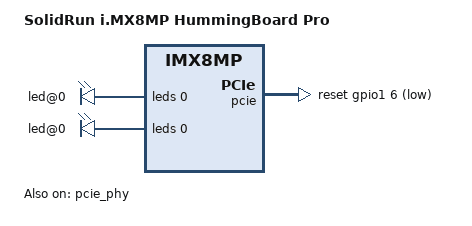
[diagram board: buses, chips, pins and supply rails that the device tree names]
// SPDX-License-Identifier: (GPL-2.0+ OR MIT)
/*
 * Copyright 2025 Josua Mayer <josua@solid-run.com>
 */

/dts-v1/;

#include <dt-bindings/phy/phy-imx8-pcie.h>

#include "imx8mp-sr-som.dtsi"
#include "imx8mp-hummingboard-pulse-codec.dtsi"
#include "imx8mp-hummingboard-pulse-common.dtsi"
#include "imx8mp-hummingboard-pulse-hdmi.dtsi"
#include "imx8mp-hummingboard-pulse-m2con.dtsi"
#include "imx8mp-hummingboard-pulse-mini-hdmi.dtsi"

/ {
	model = "SolidRun i.MX8MP HummingBoard Pro";
	compatible = "solidrun,imx8mp-hummingboard-pro",
		     "solidrun,imx8mp-sr-som", "fsl,imx8mp";

	aliases {
		ethernet0 = &eqos;
		ethernet1 = &fec;
	};
};

&iomuxc {
	pinctrl-names = "default";
	pinctrl-0 = <&mikro_pwm_pins>, <&mikro_int_pins>, <&hdmi_pins>,
		    <&m2_wwan_wake_pins>;
};

&pcie {
	pinctrl-0 = <&m2_reset_pins>;
	pinctrl-names = "default";
	reset-gpio = <&gpio1 6 GPIO_ACTIVE_LOW>;
	status = "okay";
};

&pcie_phy {
	clocks = <&hsio_blk_ctrl>;
	clock-names = "ref";
	fsl,clkreq-unsupported;
	fsl,refclk-pad-mode = <IMX8_PCIE_REFCLK_PAD_OUTPUT>;
	status = "okay";
};

&phy0 {
	leds {
		/* ADIN1300 LED_0 pin */
		led@0 {
			reg = <0>;
			color = <LED_COLOR_ID_ORANGE>;
			function = LED_FUNCTION_LAN;
			default-state = "keep";
		};

		/delete-node/ led@1;
	};
};

&phy1 {
	leds {
		#address-cells = <1>;
		#size-cells = <0>;

		/* ADIN1300 LED_0 pin */
		led@0 {
			reg = <0>;
			color = <LED_COLOR_ID_GREEN>;
			function = LED_FUNCTION_LAN;
			default-state = "keep";
		};
	};
};
